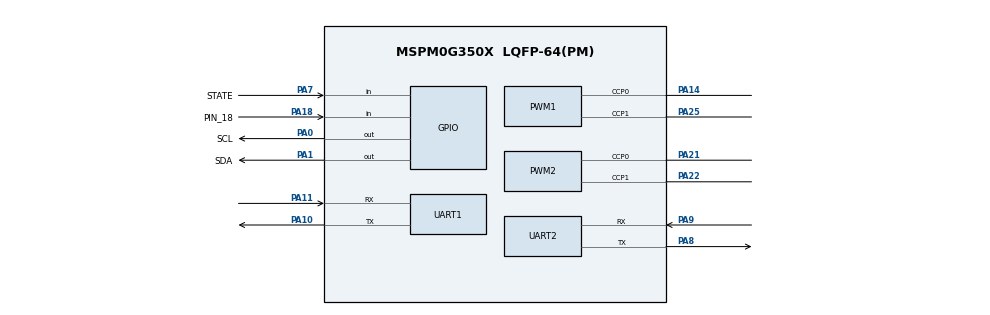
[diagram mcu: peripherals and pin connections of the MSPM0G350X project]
/**
 * @cliArgs --device "MSPM0G350X" --package "LQFP-64(PM)" --part "Default" --product "mspm0_sdk@2.01.00.03"
 * @versions {"tool":"1.20.0+3587"}
 */

/**
 * Import the modules used in this configuration.
 */
const GPIO    = scripting.addModule("/ti/driverlib/GPIO", {}, false);
const GPIO1   = GPIO.addInstance();
const GPIO2   = GPIO.addInstance();
const GPIO3   = GPIO.addInstance();
const GPIO4   = GPIO.addInstance();
const GPIO5   = GPIO.addInstance();
const GPIO6   = GPIO.addInstance();
const PWM     = scripting.addModule("/ti/driverlib/PWM", {}, false);
const PWM1    = PWM.addInstance();
const PWM2    = PWM.addInstance();
const SYSCTL  = scripting.addModule("/ti/driverlib/SYSCTL");
const SYSTICK = scripting.addModule("/ti/driverlib/SYSTICK");
const TIMER   = scripting.addModule("/ti/driverlib/TIMER", {}, false);
const TIMER1  = TIMER.addInstance();
const UART    = scripting.addModule("/ti/driverlib/UART", {}, false);
const UART1   = UART.addInstance();
const UART2   = UART.addInstance();

/**
 * Write custom configuration values to the imported modules.
 */
const gate7  = system.clockTree["MFCLKGATE"];
gate7.enable = true;

GPIO1.$name                              = "LED1";
GPIO1.port                               = "PORTA";
GPIO1.associatedPins[0].internalResistor = "PULL_DOWN";
GPIO1.associatedPins[0].$name            = "PIN_27";
GPIO1.associatedPins[0].assignedPin      = "27";

const Board = scripting.addModule("/ti/driverlib/Board", {}, false);

GPIO2.$name                              = "KEY";
GPIO2.port                               = "PORTA";
GPIO2.associatedPins[0].$name            = "PIN_18";
GPIO2.associatedPins[0].direction        = "INPUT";
GPIO2.associatedPins[0].assignedPin      = "18";
GPIO2.associatedPins[0].internalResistor = "PULL_DOWN";
GPIO2.associatedPins[0].interruptEn      = true;
GPIO2.associatedPins[0].polarity         = "RISE";
GPIO2.associatedPins[0].pin.$assign      = "PA18";

GPIO3.port                           = "PORTA";
GPIO3.$name                          = "GPIO";
GPIO3.associatedPins.create(2);
GPIO3.associatedPins[0].$name        = "SCL";
GPIO3.associatedPins[0].initialValue = "SET";
GPIO3.associatedPins[0].ioStructure  = "OD";
GPIO3.associatedPins[0].assignedPin  = "0";
GPIO3.associatedPins[0].pin.$assign  = "PA0";
GPIO3.associatedPins[1].$name        = "SDA";
GPIO3.associatedPins[1].ioStructure  = "OD";
GPIO3.associatedPins[1].initialValue = "SET";
GPIO3.associatedPins[1].assignedPin  = "1";
GPIO3.associatedPins[1].pin.$assign  = "PA1";

GPIO4.$name                              = "GPIO_Encoder";
GPIO4.port                               = "PORTB";
GPIO4.associatedPins.create(4);
GPIO4.associatedPins[0].$name            = "PIN_Right_A";
GPIO4.associatedPins[0].direction        = "INPUT";
GPIO4.associatedPins[0].assignedPin      = "2";
GPIO4.associatedPins[0].interruptEn      = true;
GPIO4.associatedPins[0].polarity         = "RISE";
GPIO4.associatedPins[0].internalResistor = "PULL_DOWN";
GPIO4.associatedPins[1].direction        = "INPUT";
GPIO4.associatedPins[1].$name            = "PIN_Right_B";
GPIO4.associatedPins[1].assignedPin      = "3";
GPIO4.associatedPins[1].internalResistor = "PULL_DOWN";
GPIO4.associatedPins[2].$name            = "PIN_Left_A";
GPIO4.associatedPins[2].direction        = "INPUT";
GPIO4.associatedPins[2].assignedPin      = "6";
GPIO4.associatedPins[2].interruptEn      = true;
GPIO4.associatedPins[2].polarity         = "RISE";
GPIO4.associatedPins[2].internalResistor = "PULL_DOWN";
GPIO4.associatedPins[3].$name            = "PIN_Left_B";
GPIO4.associatedPins[3].direction        = "INPUT";
GPIO4.associatedPins[3].assignedPin      = "7";
GPIO4.associatedPins[3].internalResistor = "PULL_DOWN";

GPIO5.$name                         = "GPIO_LineGet";
GPIO5.port                          = "PORTB";
GPIO5.associatedPins.create(4);
GPIO5.associatedPins[0].$name       = "PIN_Line_Left1";
GPIO5.associatedPins[0].direction   = "INPUT";
GPIO5.associatedPins[0].assignedPin = "19";
GPIO5.associatedPins[1].$name       = "PIN_Line_Left2";
GPIO5.associatedPins[1].direction   = "INPUT";
GPIO5.associatedPins[1].assignedPin = "18";
GPIO5.associatedPins[2].$name       = "PIN_Line_Right1";
GPIO5.associatedPins[2].direction   = "INPUT";
GPIO5.associatedPins[2].assignedPin = "20";
GPIO5.associatedPins[3].$name       = "PIN_Line_Right2";
GPIO5.associatedPins[3].direction   = "INPUT";
GPIO5.associatedPins[3].assignedPin = "24";

GPIO6.$name                         = "HC05";
GPIO6.port                          = "PORTA";
GPIO6.associatedPins[0].$name       = "STATE";
GPIO6.associatedPins[0].direction   = "INPUT";
GPIO6.associatedPins[0].assignedPin = "7";
GPIO6.associatedPins[0].pin.$assign = "PA7";

PWM1.clockDivider                       = 8;
PWM1.timerStartTimer                    = true;
PWM1.$name                              = "PWM_MotorB";
PWM1.timerCount                         = 4000;
PWM1.peripheral.$assign                 = "TIMG12";
PWM1.peripheral.ccp0Pin.$assign         = "PA14";
PWM1.peripheral.ccp1Pin.$assign         = "PA25";
PWM1.PWM_CHANNEL_0.$name                = "ti_driverlib_pwm_PWMTimerCC0";
PWM1.PWM_CHANNEL_0.dutyCycle            = 70;
PWM1.PWM_CHANNEL_1.$name                = "ti_driverlib_pwm_PWMTimerCC3";
PWM1.PWM_CHANNEL_1.ccValue              = 1199;
PWM1.PWM_CHANNEL_1.dutyCycle            = 70;
PWM1.ccp0PinConfig.direction            = scripting.forceWrite("OUTPUT");
PWM1.ccp0PinConfig.hideOutputInversion  = scripting.forceWrite(false);
PWM1.ccp0PinConfig.onlyInternalResistor = scripting.forceWrite(false);
PWM1.ccp0PinConfig.passedPeripheralType = scripting.forceWrite("Digital");
PWM1.ccp0PinConfig.$name                = "ti_driverlib_gpio_GPIOPinGeneric2";
PWM1.ccp1PinConfig.direction            = scripting.forceWrite("OUTPUT");
PWM1.ccp1PinConfig.hideOutputInversion  = scripting.forceWrite(false);
PWM1.ccp1PinConfig.onlyInternalResistor = scripting.forceWrite(false);
PWM1.ccp1PinConfig.passedPeripheralType = scripting.forceWrite("Digital");
PWM1.ccp1PinConfig.$name                = "ti_driverlib_gpio_GPIOPinGeneric5";

PWM2.$name                              = "PWM_MotorA";
PWM2.timerStartTimer                    = true;
PWM2.clockDivider                       = 8;
PWM2.timerCount                         = 4000;
PWM2.peripheral.$assign                 = "TIMG6";
PWM2.peripheral.ccp0Pin.$assign         = "PA21";
PWM2.peripheral.ccp1Pin.$assign         = "PA22";
PWM2.PWM_CHANNEL_0.$name                = "ti_driverlib_pwm_PWMTimerCC1";
PWM2.PWM_CHANNEL_0.dutyCycle            = 70;
PWM2.PWM_CHANNEL_1.$name                = "ti_driverlib_pwm_PWMTimerCC2";
PWM2.PWM_CHANNEL_1.ccValue              = 1199;
PWM2.PWM_CHANNEL_1.dutyCycle            = 70;
PWM2.ccp0PinConfig.direction            = scripting.forceWrite("OUTPUT");
PWM2.ccp0PinConfig.hideOutputInversion  = scripting.forceWrite(false);
PWM2.ccp0PinConfig.onlyInternalResistor = scripting.forceWrite(false);
PWM2.ccp0PinConfig.passedPeripheralType = scripting.forceWrite("Digital");
PWM2.ccp0PinConfig.$name                = "ti_driverlib_gpio_GPIOPinGeneric3";
PWM2.ccp1PinConfig.direction            = scripting.forceWrite("OUTPUT");
PWM2.ccp1PinConfig.hideOutputInversion  = scripting.forceWrite(false);
PWM2.ccp1PinConfig.onlyInternalResistor = scripting.forceWrite(false);
PWM2.ccp1PinConfig.passedPeripheralType = scripting.forceWrite("Digital");
PWM2.ccp1PinConfig.$name                = "ti_driverlib_gpio_GPIOPinGeneric4";

SYSCTL.forceDefaultClkConfig = true;
SYSCTL.clockTreeEn           = true;

SYSTICK.periodEnable      = true;
SYSTICK.systickEnable     = true;
SYSTICK.interruptPriority = "0";
SYSTICK.period            = 32;

TIMER1.$name              = "TIMER_0";
TIMER1.timerMode          = "PERIODIC";
TIMER1.timerStartTimer    = true;
TIMER1.timerClkDiv        = 8;
TIMER1.timerClkPrescale   = 256;
TIMER1.interrupts         = ["ZERO"];
TIMER1.timerPeriod        = "50ms";
TIMER1.interruptPriority  = "3";
TIMER1.peripheral.$assign = "TIMG7";

UART1.enabledInterrupts                = ["RX"];
UART1.$name                            = "USB_TLL";
UART1.targetBaudRate                   = 115200;
UART1.peripheral.$assign               = "UART0";
UART1.peripheral.rxPin.$assign         = "PA11";
UART1.peripheral.txPin.$assign         = "PA10";
UART1.txPinConfig.direction            = scripting.forceWrite("OUTPUT");
UART1.txPinConfig.hideOutputInversion  = scripting.forceWrite(false);
UART1.txPinConfig.onlyInternalResistor = scripting.forceWrite(false);
UART1.txPinConfig.passedPeripheralType = scripting.forceWrite("Digital");
UART1.txPinConfig.$name                = "ti_driverlib_gpio_GPIOPinGeneric0";
UART1.rxPinConfig.hideOutputInversion  = scripting.forceWrite(false);
UART1.rxPinConfig.onlyInternalResistor = scripting.forceWrite(false);
UART1.rxPinConfig.passedPeripheralType = scripting.forceWrite("Digital");
UART1.rxPinConfig.$name                = "ti_driverlib_gpio_GPIOPinGeneric1";

UART2.$name                            = "UART_Trans";
UART2.uartClkSrc                       = "MFCLK";
UART2.enabledInterrupts                = ["RX"];
UART2.interruptPriority                = "1";
UART2.peripheral.$assign               = "UART1";
UART2.peripheral.rxPin.$assign         = "PA9";
UART2.peripheral.txPin.$assign         = "PA8";
UART2.txPinConfig.$name                = "ti_driverlib_gpio_GPIOPinGeneric6";
UART2.txPinConfig.direction            = scripting.forceWrite("OUTPUT");
UART2.txPinConfig.hideOutputInversion  = scripting.forceWrite(false);
UART2.txPinConfig.onlyInternalResistor = scripting.forceWrite(false);
UART2.txPinConfig.passedPeripheralType = scripting.forceWrite("Digital");
UART2.rxPinConfig.$name                = "ti_driverlib_gpio_GPIOPinGeneric7";
UART2.rxPinConfig.hideOutputInversion  = scripting.forceWrite(false);
UART2.rxPinConfig.onlyInternalResistor = scripting.forceWrite(false);
UART2.rxPinConfig.passedPeripheralType = scripting.forceWrite("Digital");

/**
 * Pinmux solution for unlocked pins/peripherals. This ensures that minor changes to the automatic solver in a future
 * version of the tool will not impact the pinmux you originally saw.  These lines can be completely deleted in order to
 * re-solve from scratch.
 */
GPIO1.associatedPins[0].pin.$suggestSolution = "PA27";
Board.peripheral.$suggestSolution            = "DEBUGSS";
Board.peripheral.swclkPin.$suggestSolution   = "PA20";
Board.peripheral.swdioPin.$suggestSolution   = "PA19";
GPIO4.associatedPins[0].pin.$suggestSolution = "PB2";
GPIO4.associatedPins[1].pin.$suggestSolution = "PB3";
GPIO4.associatedPins[2].pin.$suggestSolution = "PB6";
GPIO4.associatedPins[3].pin.$suggestSolution = "PB7";
GPIO5.associatedPins[0].pin.$suggestSolution = "PB19";
GPIO5.associatedPins[1].pin.$suggestSolution = "PB18";
GPIO5.associatedPins[2].pin.$suggestSolution = "PB20";
GPIO5.associatedPins[3].pin.$suggestSolution = "PB24";
